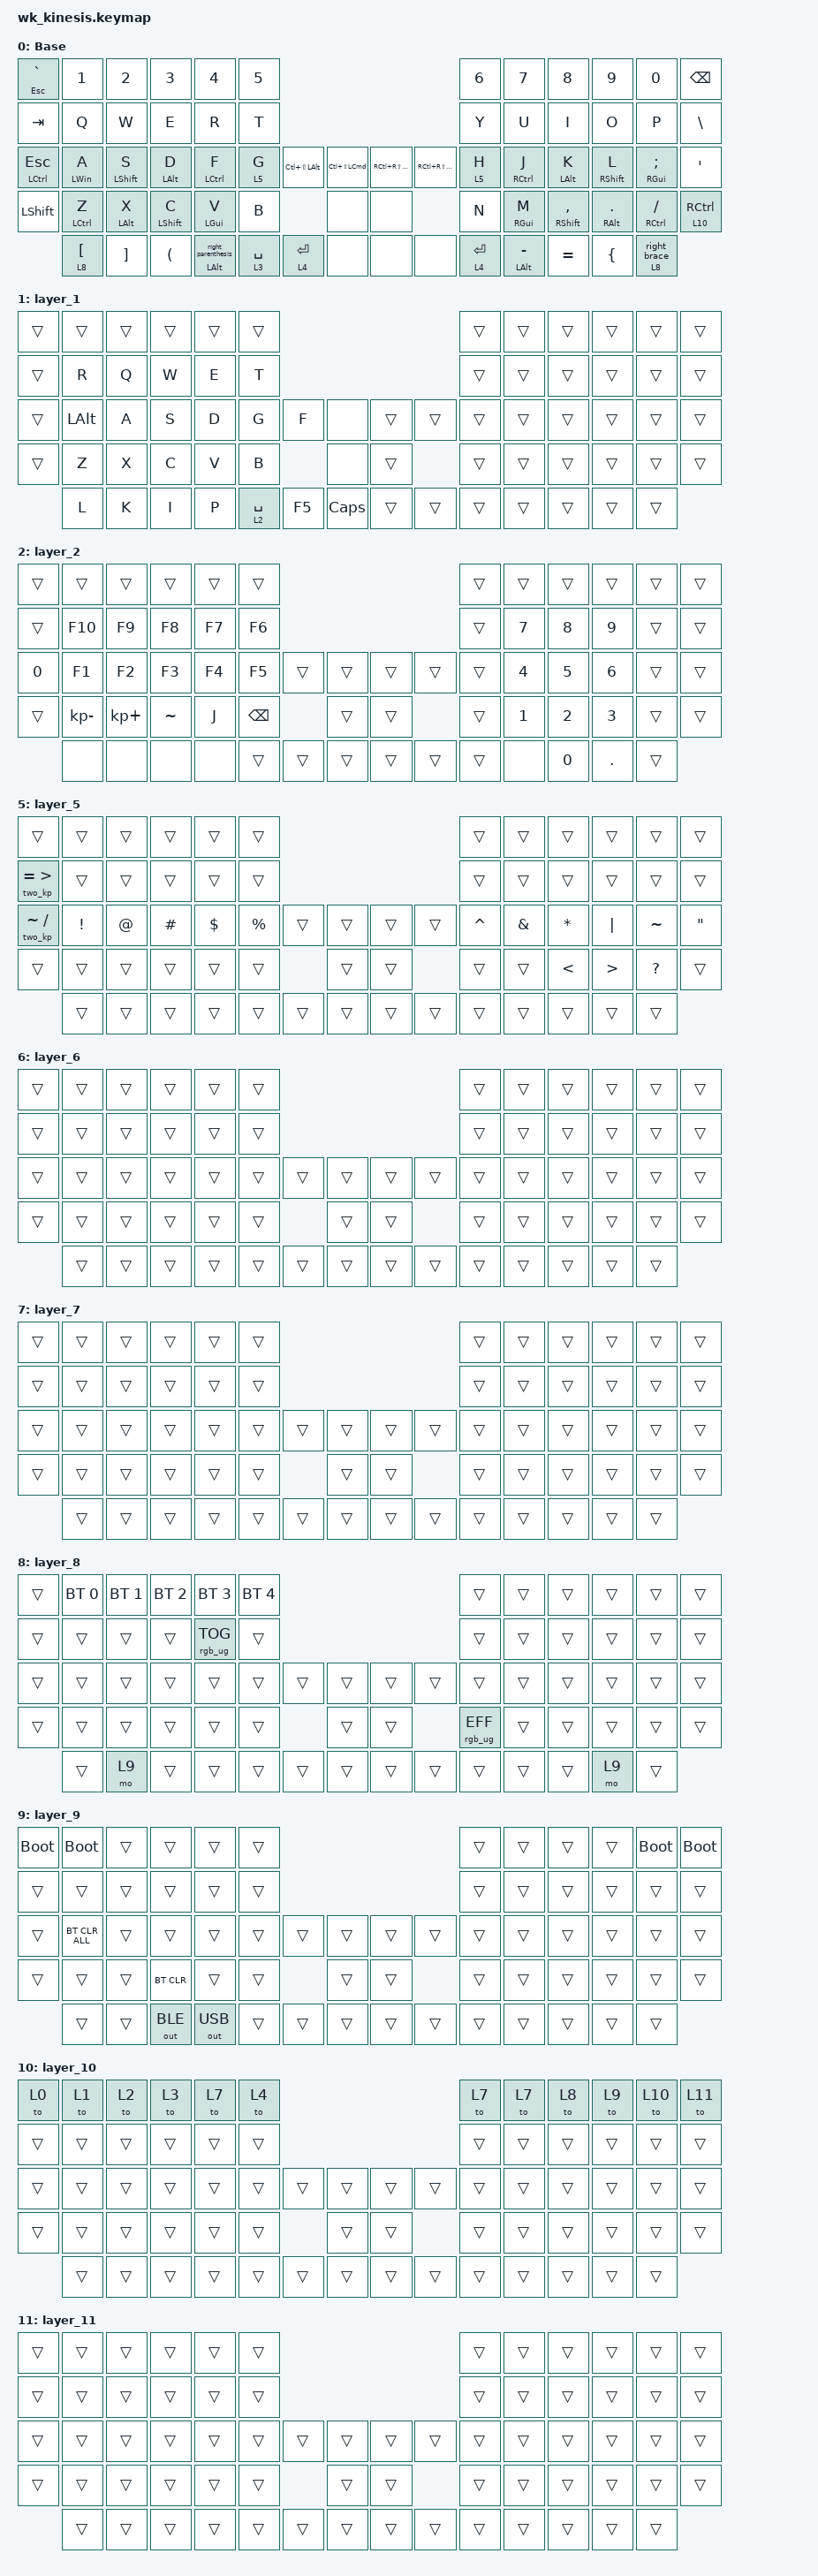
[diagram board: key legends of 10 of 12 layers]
#include <behaviors.dtsi>
#include <dt-bindings/zmk/bt.h>
#include <dt-bindings/zmk/keys.h>
#include <dt-bindings/zmk/outputs.h>
#include <dt-bindings/zmk/rgb.h>

/ {
    behaviors {
        hm: homerow_mods {
            compatible = "zmk,behavior-hold-tap";
            label = "HOMEROW_MODS";
            #binding-cells = <2>;
            tapping-term-ms = <160>;
            flavor = "balanced";
            bindings = <&kp>, <&kp>;

            quick-tap-ms = <100>;
            require-prior-idle-ms = <130>;
        };

        hm_lt: homerow_mods_lt {
            compatible = "zmk,behavior-hold-tap";
            label = "HOMEROW_MODS_LT";
            #binding-cells = <2>;
            tapping-term-ms = <160>;
            flavor = "balanced";
            quick-tap-ms = <100>;
            require-prior-idle-ms = <130>;
            bindings = <&mo>, <&kp>;
        };

        bspc_del: backspace_delete {
            compatible = "zmk,behavior-mod-morph";
            label = "BSPC_DEL";
            bindings = <&kp BACKSPACE>, <&kp DELETE>;

            #binding-cells = <0>;
            mods = <(MOD_LSFT|MOD_RSFT)>;
            keep-mods = <(MOD_RSFT)>;
        };

        bspc_del_lt: backspace_delelte_layer_tap {
            compatible = "zmk,behavior-hold-tap";
            label = "BSPC_DEL_LT";
            bindings = <&mo>, <&bspc_del>;

            #binding-cells = <2>;
            tapping-term-ms = <200>;
            flavor = "balanced";
            quick-tap-ms = <175>;
        };

        pbrc_left: ParenthesisOrBraceLeft {
            compatible = "zmk,behavior-mod-morph";
            label = "PARENBRACELEFT";
            bindings = <&kp LEFT_PARENTHESIS>, <&kp LEFT_BRACE>;

            #binding-cells = <0>;
            mods = <(MOD_LSFT|MOD_RSFT)>;
        };

        pbrc_right: ParenthesisOrBraceRight {
            compatible = "zmk,behavior-mod-morph";
            label = "PARENBRACERight";
            bindings = <&kp RIGHT_PARENTHESIS>, <&kp RIGHT_BRACE>;

            #binding-cells = <0>;
            mods = <(MOD_LSFT|MOD_RSFT)>;
        };

        hm_lt_arrow: hm_lt_arrow {
            compatible = "zmk,behavior-hold-tap";
            label = "HM_LT_ARROW";
            #binding-cells = <2>;
            tapping-term-ms = <160>;
            flavor = "balanced";
            quick-tap-ms = <100>;
            require-prior-idle-ms = <130>;
            bindings = <&mo>, <&none>;
        };

        hm_lt_bspc_del: hm_lt_bspc_del {
            compatible = "zmk,behavior-hold-tap";
            label = "HM_LT_BSPC_DEL";
            #binding-cells = <2>;
            tapping-term-ms = <170>;
            flavor = "balanced";
            quick-tap-ms = <120>;
            require-prior-idle-ms = <200>;
            bindings = <&mo>, <&bspc_del>;
        };

        long_hold: long_hold {
            compatible = "zmk,behavior-hold-tap";
            label = "LONG_HOLD";
            #binding-cells = <2>;
            tapping-term-ms = <300>;
            flavor = "tap-preferred";
            bindings = <&kp>, <&kp>;

            quick-tap-ms = <200>;
            require-prior-idle-ms = <200>;
        };

        hm_arrow: hm_arrow {
            compatible = "zmk,behavior-hold-tap";
            label = "HM_ARROW";
            #binding-cells = <2>;
            tapping-term-ms = <160>;
            flavor = "balanced";
            quick-tap-ms = <100>;
            require-prior-idle-ms = <130>;
            bindings = <&kp>, <&arrow>;
        };

        td_layer_switch: td_layer_switch {
            compatible = "zmk,behavior-tap-dance";
            label = "TD_LAYER_SWITCH";
            #binding-cells = <0>;
            bindings = <&sl 10>, <&to 0>;
        };

        hm_lt_ctrl: hm_lt_ctrl {
            compatible = "zmk,behavior-hold-tap";
            label = "HM_LT_CTRL";
            #binding-cells = <2>;
            tapping-term-ms = <160>;
            flavor = "balanced";
            quick-tap-ms = <100>;
            require-prior-idle-ms = <130>;
            bindings = <&mo_ctrl>, <&kp>;
        };

        hm_mo_ctrl_shift_super: hm_mo_ctrl_shift_super {
            compatible = "zmk,behavior-hold-tap";
            label = "HM_MO_CTRL_SHIFT_SUPER";
            #binding-cells = <2>;
            tapping-term-ms = <160>;
            flavor = "balanced";
            quick-tap-ms = <100>;
            require-prior-idle-ms = <130>;
            bindings = <&mo_ctrl_shift_super>, <&kp>;
        };

        hm_mo_ctrl_alt_super: hm_mo_ctrl_alt_super {
            compatible = "zmk,behavior-hold-tap";
            label = "HM_MO_CTRL_ALT_SUPER";
            #binding-cells = <2>;
            tapping-term-ms = <160>;
            flavor = "balanced";
            quick-tap-ms = <100>;
            require-prior-idle-ms = <130>;
            bindings = <&mo_ctrl_alt_super>, <&kp>;
        };

        hm_left_parenthesis: hm_left_parenthesis {
            compatible = "zmk,behavior-hold-tap";
            label = "HM_LEFT_PARENTHESIS";
            #binding-cells = <2>;
            tapping-term-ms = <160>;
            flavor = "balanced";
            bindings = <&kp>, <&left_parenthesis>;

            quick-tap-ms = <100>;
            require-prior-idle-ms = <130>;
        };

        hm_right_parenthesis: hm_right_parenthesis {
            compatible = "zmk,behavior-hold-tap";
            label = "HM_RIGHT_PARENTHESIS";
            #binding-cells = <2>;
            tapping-term-ms = <160>;
            flavor = "balanced";
            bindings = <&kp>, <&right_parenthesis>;

            quick-tap-ms = <100>;
            require-prior-idle-ms = <130>;
        };

        hm_lt_right_brace: hm_lt_right_brace {
            compatible = "zmk,behavior-hold-tap";
            label = "HM_LT_RIGHT_BRACE";
            #binding-cells = <2>;
            tapping-term-ms = <160>;
            flavor = "balanced";
            quick-tap-ms = <100>;
            require-prior-idle-ms = <130>;
            bindings = <&mo>, <&right_brace>;
        };
    };

    combos { compatible = "zmk,combos"; };

    macros {
        arrow: arrow {
            compatible = "zmk,behavior-macro";
            #binding-cells = <0>;
            bindings = <&kp EQUAL &kp GT>;
            label = "ARROW";
        };

        two_kp: param_arrow {
            compatible = "zmk,behavior-macro-two-param";
            #binding-cells = <2>;
            bindings = <&macro_param_1to1 &kp MACRO_PLACEHOLDER &macro_param_2to1 &kp MACRO_PLACEHOLDER>;
            label = "PARAM_ARROW";
        };

        mo_ctrl: ctrl_mo {
            compatible = "zmk,behavior-macro-one-param";
            #binding-cells = <1>;
            bindings =
                <&macro_press>,
                <&macro_param_1to1 &mo MACRO_PLACEHOLDER &kp LCTRL>,
                <&macro_pause_for_release>,
                <&macro_release>,
                <&macro_param_1to1 &mo MACRO_PLACEHOLDER &kp LCTRL>;

            label = "CTRL_MO";
        };

        mo_alt: mo_ctrl_super {
            compatible = "zmk,behavior-macro-one-param";
            #binding-cells = <1>;
            bindings =
                <&macro_press>,
                <&macro_param_1to1 &mo MACRO_PLACEHOLDER &kp LEFT_ALT>,
                <&macro_pause_for_release>,
                <&macro_release>,
                <&macro_param_1to1 &mo MACRO_PLACEHOLDER &kp LEFT_ALT>;

            label = "MO_CTRL_SUPER";
        };

        mo_shift: mo_shift {
            compatible = "zmk,behavior-macro-one-param";
            #binding-cells = <1>;
            bindings =
                <&macro_press>,
                <&macro_param_1to1 &mo MACRO_PLACEHOLDER &kp LEFT_SHIFT>,
                <&macro_pause_for_release>,
                <&macro_release>,
                <&macro_param_1to1 &mo MACRO_PLACEHOLDER &kp LEFT_SHIFT>;

            label = "MO_SHIFT";
        };

        mo_ctrl_shift_super: mo_ctrl_shift_super {
            compatible = "zmk,behavior-macro-one-param";
            #binding-cells = <1>;
            bindings =
                <&macro_press>,
                <&macro_param_1to1 &mo MACRO_PLACEHOLDER &kp LC(LS(LGUI))>,
                <&macro_pause_for_release>,
                <&macro_release>,
                <&macro_param_1to1 &mo MACRO_PLACEHOLDER &kp LC(LS(LGUI))>;

            label = "MO_CTRL_SHIFT_SUPER";
        };

        mo_ctrl_alt_super: mo_ctrl_alt_super {
            compatible = "zmk,behavior-macro-one-param";
            #binding-cells = <1>;
            bindings =
                <&macro_press>,
                <&macro_param_1to1 &mo MACRO_PLACEHOLDER &kp LC(LA(LGUI))>,
                <&macro_pause_for_release>,
                <&macro_release>,
                <&macro_param_1to1 &mo MACRO_PLACEHOLDER &kp LC(LA(LGUI))>;

            label = "MO_CTRL_ALT_SUPER";
        };

        left_parenthesis: left_parenthesis {
            compatible = "zmk,behavior-macro";
            #binding-cells = <0>;
            bindings =
                <&macro_press>,
                <&kp LEFT_SHIFT &kp N9>,
                <&macro_pause_for_release>,
                <&macro_release>,
                <&kp LEFT_SHIFT &kp N9>,
                <&macro_press>;

            label = "LEFT_PARENTHESIS";
        };

        right_parenthesis: right_parenthesis {
            compatible = "zmk,behavior-macro";
            #binding-cells = <0>;
            bindings =
                <&macro_press>,
                <&kp LEFT_SHIFT &kp N0>,
                <&macro_pause_for_release>,
                <&macro_release>,
                <&kp LEFT_SHIFT &kp N0>,
                <&macro_press>;

            label = "RIGHT_PARENTHESIS";
        };

        left_brace: left_brace {
            compatible = "zmk,behavior-macro";
            #binding-cells = <0>;
            bindings =
                <&macro_press>,
                <&kp LEFT_SHIFT &kp LEFT_BRACKET>,
                <&macro_pause_for_release>,
                <&macro_release>,
                <&kp LEFT_SHIFT &kp LEFT_BRACKET>,
                <&macro_press>;

            label = "LEFT_BRACE";
        };

        right_brace: right_brace {
            compatible = "zmk,behavior-macro";
            #binding-cells = <0>;
            bindings =
                <&macro_press>,
                <&kp LEFT_SHIFT &kp RIGHT_BRACKET>,
                <&macro_pause_for_release>,
                <&macro_release>,
                <&kp LEFT_SHIFT &kp RIGHT_BRACKET>,
                <&macro_press>;

            label = "RIGHT_BRACE";
        };
    };

    keymap {
        compatible = "zmk,keymap";

        default_layer {
            display-name = "Base";
            bindings = <
&hm ESCAPE GRAVE         &kp N1                 &kp N2             &kp N3                &kp N4                            &kp N5                                                                                                                                            &kp N6      &kp N7               &kp N8                 &kp N9             &kp N0                  &kp BACKSPACE
&kp TAB                  &kp Q                  &kp W              &kp E                 &kp R                             &kp T                                                                                                                                             &kp Y       &kp U                &kp I                  &kp O              &kp P                   &kp BACKSLASH
&mt LEFT_CONTROL ESCAPE  &hm LEFT_WIN A         &hm LEFT_SHIFT S   &hm LEFT_ALT D        &hm LEFT_CONTROL F                &hm_lt 5 G                  &kp LC(LS(LEFT_ALT))  &kp LC(LS(LEFT_COMMAND))      &kp RC(RS(RIGHT_COMMAND))  &kp RC(RS(RIGHT_ALT))                  &hm_lt 5 H  &hm RIGHT_CONTROL J  &hm LEFT_ALT K         &hm RIGHT_SHIFT L  &hm RIGHT_GUI SEMI      &kp SINGLE_QUOTE
&kp LEFT_SHIFT           &hm LEFT_CONTROL Z     &hm LEFT_ALT X     &hm LEFT_SHIFT C      &hm LEFT_GUI V                    &kp B                                             &none                         &none                                                             &kp N       &hm RIGHT_GUI M      &hm RIGHT_SHIFT COMMA  &hm RIGHT_ALT DOT  &hm RIGHT_CONTROL FSLH  &hm_lt 10 RCTRL
                         &hm_lt 8 LEFT_BRACKET  &kp RIGHT_BRACKET  &kp LEFT_PARENTHESIS  &hm_right_parenthesis LEFT_ALT 0              &hm_lt 3 SPACE  &hm_lt 4 ENTER        &none                         &none                      &none                  &hm_lt 4 ENTER              &hm LALT MINUS       &kp EQUAL              &kp LEFT_BRACE     &hm_lt_right_brace 8 0
            >;
        };

        layer_1 {
            bindings = <
&trans  &trans    &trans  &trans  &trans  &trans                                                                    &trans  &trans  &trans  &trans  &trans  &trans
&trans  &kp R     &kp Q   &kp W   &kp E   &kp T                                                                     &trans  &trans  &trans  &trans  &trans  &trans
&trans  &kp LALT  &kp A   &kp S   &kp D   &kp G                   &kp F   &none             &trans  &trans          &trans  &trans  &trans  &trans  &trans  &trans
&trans  &kp Z     &kp X   &kp C   &kp V   &kp B                           &none             &trans                  &trans  &trans  &trans  &trans  &trans  &trans
        &kp L     &kp K   &kp I   &kp P           &hm_lt 2 SPACE  &kp F5  &kp CAPSLOCK      &trans  &trans  &trans          &trans  &trans  &trans  &trans
            >;
        };

        layer_2 {
            bindings = <
&trans  &trans        &trans       &trans     &trans  &trans                                                             &trans  &trans        &trans        &trans        &trans  &trans
&trans  &kp F10       &kp F9       &kp F8     &kp F7  &kp F6                                                             &trans  &kp NUMBER_7  &kp NUMBER_8  &kp NUMBER_9  &trans  &trans
&kp N0  &kp F1        &kp F2       &kp F3     &kp F4  &kp F5                 &trans  &trans      &trans  &trans          &trans  &kp NUMBER_4  &kp NUMBER_5  &kp NUMBER_6  &trans  &trans
&trans  &kp KP_MINUS  &kp KP_PLUS  &kp TILDE  &kp J   &kp BACKSPACE                  &trans      &trans                  &trans  &kp NUMBER_1  &kp NUMBER_2  &kp NUMBER_3  &trans  &trans
        &none         &none        &none      &none                  &trans  &trans  &trans      &trans  &trans  &trans          &none         &kp NUMBER_0  &kp PERIOD    &trans
            >;
        };

        layer_3 {
            bindings = <
&kp F11            &kp F1                             &kp F2                               &kp F3                             &kp F4                                 &kp F5                                                                              &kp F6          &kp F7                   &kp F8                   &kp F9                       &kp F10            &kp F12
&kp LC(LA(LS(N)))  &kp LC(LA(LS(NUMBER_6)))           &kp LC(LS(LA(NUMBER_7)))             &kp LC(LS(LA(NUMBER_8)))           &kp LC(LS(LA(NUMBER_9)))               &kp LC(LA(LS(Z)))                                                                   &none           &none                    &none                    &none                        &none              &none
&kp CAPSLOCK       &hm LEFT_GUI LC(LA(LS(NUMBER_1)))  &hm LEFT_SHIFT LC(LA(LS(NUMBER_2)))  &hm LEFT_ALT LC(LA(LS(NUMBER_3)))  &hm LEFT_CONTROL LC(LA(LS(NUMBER_4)))  &kp LC(LA(LS(NUMBER_5)))         &none  &none      &none  &none                     &kp LEFT_ARROW  &hm RIGHT_CONTROL DOWN   &hm RIGHT_ALT UP_ARROW   &hm RIGHT_SHIFT RIGHT_ARROW  &kp RIGHT_GUI      &none
&none              &hm LEFT_CONTROL DELETE            &hm LEFT_ALT BACKSPACE               &hm LEFT_SHIFT LC(LS(C))           &hm LWIN INSERT                        &kp ENTER                               &none      &none                            &kp HOME        &hm RIGHT_GUI PAGE_DOWN  &hm RIGHT_SHIFT PAGE_UP  &hm RIGHT_ALT END            &kp RIGHT_CONTROL  &none
                   &kp LC(LA(LS(LEFT)))               &kp LC(LA(LS(UP)))                   &kp LC(LA(LS(DOWN)))               &kp LC(LA(LS(RIGHT)))                                            &none  &none  &none      &none  &none  &kp LC(LA(LS(N)))                  &none                    &none                    &none                        &none
            >;
        };

        layer_4 {
            bindings = <
&none  &none                 &none                 &none                 &none                 &none                                                               &none                       &none                       &none                     &none                        &none  &none
&none  &kp LA(LS(NUMBER_6))  &kp LA(LS(NUMBER_7))  &kp LA(LS(NUMBER_8))  &kp LA(LS(NUMBER_9))  &kp LA(LS(Z))                                                       &none                       &none                       &none                     &none                        &none  &none
&none  &kp LA(LS(NUMBER_1))  &kp LA(LS(NUMBER_2))  &kp LA(LS(NUMBER_3))  &kp LA(LS(NUMBER_4))  &kp LA(LS(NUMBER_5))         &none  &none      &none  &none         &kp LC(LA(LS(LEFT_ARROW)))  &kp LC(LA(LS(DOWN_ARROW)))  &kp LC(LA(LS(UP_ARROW)))  &kp LC(LA(LS(RIGHT_ARROW)))  &none  &none
&none  &none                 &none                 &none                 &none                 &none                               &none      &none                &none                       &none                       &none                     &none                        &none  &none
       &none                 &none                 &none                 &none                                       &none  &none  &none      &none  &none  &none                              &none                       &none                     &none                        &none
            >;
        };

        layer_5 {
            bindings = <
&trans                      &trans           &trans       &trans    &trans      &trans                                                           &trans     &trans         &trans         &trans            &trans        &trans
&two_kp EQUAL GREATER_THAN  &trans           &trans       &trans    &trans      &trans                                                           &trans     &trans         &trans         &trans            &trans        &trans
&two_kp TILDE SLASH         &kp EXCLAMATION  &kp AT_SIGN  &kp HASH  &kp DOLLAR  &kp PERCENT          &trans  &trans      &trans  &trans          &kp CARET  &kp AMPERSAND  &kp ASTERISK   &kp PIPE          &kp TILDE     &kp DOUBLE_QUOTES
&trans                      &trans           &trans       &trans    &trans      &trans                       &trans      &trans                  &trans     &trans         &kp LESS_THAN  &kp GREATER_THAN  &kp QUESTION  &trans
                            &trans           &trans       &trans    &trans                   &trans  &trans  &trans      &trans  &trans  &trans             &trans         &trans         &trans            &trans
            >;
        };

        layer_6 {
            bindings = <
&trans  &trans  &trans  &trans  &trans  &trans                                                      &trans  &trans  &trans  &trans  &trans  &trans
&trans  &trans  &trans  &trans  &trans  &trans                                                      &trans  &trans  &trans  &trans  &trans  &trans
&trans  &trans  &trans  &trans  &trans  &trans          &trans  &trans      &trans  &trans          &trans  &trans  &trans  &trans  &trans  &trans
&trans  &trans  &trans  &trans  &trans  &trans                  &trans      &trans                  &trans  &trans  &trans  &trans  &trans  &trans
        &trans  &trans  &trans  &trans          &trans  &trans  &trans      &trans  &trans  &trans          &trans  &trans  &trans  &trans
            >;
        };

        layer_7 {
            bindings = <
&trans  &trans  &trans  &trans  &trans  &trans                                                      &trans  &trans  &trans  &trans  &trans  &trans
&trans  &trans  &trans  &trans  &trans  &trans                                                      &trans  &trans  &trans  &trans  &trans  &trans
&trans  &trans  &trans  &trans  &trans  &trans          &trans  &trans      &trans  &trans          &trans  &trans  &trans  &trans  &trans  &trans
&trans  &trans  &trans  &trans  &trans  &trans                  &trans      &trans                  &trans  &trans  &trans  &trans  &trans  &trans
        &trans  &trans  &trans  &trans          &trans  &trans  &trans      &trans  &trans  &trans          &trans  &trans  &trans  &trans
            >;
        };

        layer_8 {
            bindings = <
&trans  &bt BT_SEL 0  &bt BT_SEL 1  &bt BT_SEL 2  &bt BT_SEL 3     &bt BT_SEL 4                                                      &trans           &trans  &trans  &trans  &trans  &trans
&trans  &trans        &trans        &trans        &rgb_ug RGB_TOG  &trans                                                            &trans           &trans  &trans  &trans  &trans  &trans
&trans  &trans        &trans        &trans        &trans           &trans                &trans  &trans      &trans  &trans          &trans           &trans  &trans  &trans  &trans  &trans
&trans  &trans        &trans        &trans        &trans           &trans                        &trans      &trans                  &rgb_ug RGB_EFF  &trans  &trans  &trans  &trans  &trans
        &trans        &mo 9         &trans        &trans                         &trans  &trans  &trans      &trans  &trans  &trans                   &trans  &trans  &mo 9   &trans
            >;
        };

        layer_9 {
            bindings = <
&bootloader  &bootloader     &trans  &trans        &trans        &trans                                                      &trans  &trans  &trans  &trans  &bootloader  &bootloader
&trans       &trans          &trans  &trans        &trans        &trans                                                      &trans  &trans  &trans  &trans  &trans       &trans
&trans       &bt BT_CLR_ALL  &trans  &trans        &trans        &trans          &trans  &trans      &trans  &trans          &trans  &trans  &trans  &trans  &trans       &trans
&trans       &trans          &trans  &bt BT_CLR    &trans        &trans                  &trans      &trans                  &trans  &trans  &trans  &trans  &trans       &trans
             &trans          &trans  &out OUT_BLE  &out OUT_USB          &trans  &trans  &trans      &trans  &trans  &trans          &trans  &trans  &trans  &trans
            >;
        };

        layer_10 {
            bindings = <
&to 0   &to 1   &to 2   &to 3   &to 7   &to 4                                                       &to 7   &to 7   &to 8   &to 9   &to 10  &to 11
&trans  &trans  &trans  &trans  &trans  &trans                                                      &trans  &trans  &trans  &trans  &trans  &trans
&trans  &trans  &trans  &trans  &trans  &trans          &trans  &trans      &trans  &trans          &trans  &trans  &trans  &trans  &trans  &trans
&trans  &trans  &trans  &trans  &trans  &trans                  &trans      &trans                  &trans  &trans  &trans  &trans  &trans  &trans
        &trans  &trans  &trans  &trans          &trans  &trans  &trans      &trans  &trans  &trans          &trans  &trans  &trans  &trans
            >;
        };

        layer_11 {
            bindings = <
&trans  &trans  &trans  &trans  &trans  &trans                                                      &trans  &trans  &trans  &trans  &trans  &trans
&trans  &trans  &trans  &trans  &trans  &trans                                                      &trans  &trans  &trans  &trans  &trans  &trans
&trans  &trans  &trans  &trans  &trans  &trans          &trans  &trans      &trans  &trans          &trans  &trans  &trans  &trans  &trans  &trans
&trans  &trans  &trans  &trans  &trans  &trans                  &trans      &trans                  &trans  &trans  &trans  &trans  &trans  &trans
        &trans  &trans  &trans  &trans          &trans  &trans  &trans      &trans  &trans  &trans          &trans  &trans  &trans  &trans
            >;
        };
    };

    conditional_layers { compatible = "zmk,conditional-layers"; };
};
